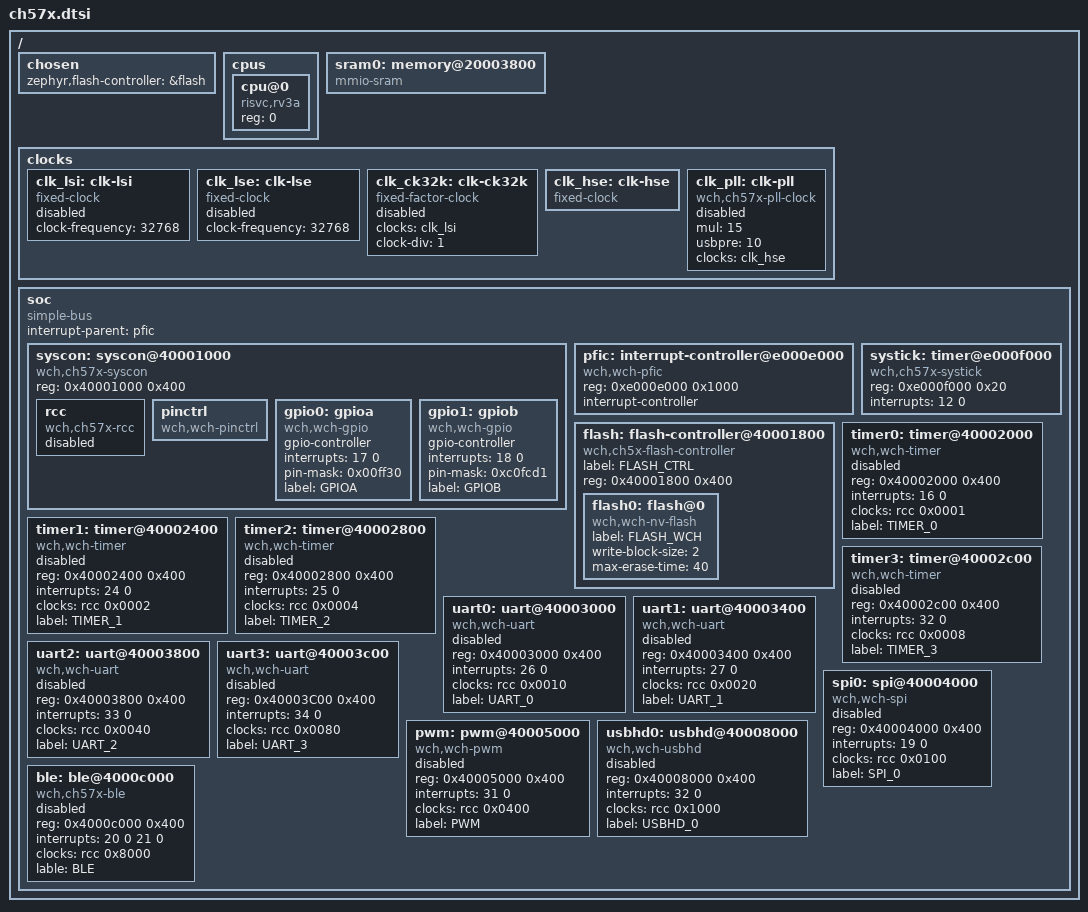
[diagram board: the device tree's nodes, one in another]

#include "skeleton.dtsi"
#include <freq.h>

/ {
	chosen {
		zephyr,flash-controller = &flash;
	};

	cpus {
		#address-cells = <1>;
		#size-cells = <0>;

		cpu@0 {
			device_type = "cpu";
			compatible = "risvc,rv3a";
			reg = <0>;
		};
	};

	sram0: memory@20003800 {
		compatible = "mmio-sram";
	};
	
	clocks {
		clk_lsi: clk-lsi {
			#clock-cells = <0>;
			compatible = "fixed-clock";
			clock-frequency = <32768>;
			status = "disabled";
		};

		clk_lse: clk-lse {
			#clock-cells = <0>;
			compatible = "fixed-clock";
			clock-frequency = <32768>;
			status = "disabled";
		};

		clk_ck32k: clk-ck32k {
			#clock-cells = <0>;
			compatible = "fixed-factor-clock";
			clocks = <&clk_lsi>;
			clock-div = <1>;
			status = "disabled";
		};

		clk_hse: clk-hse {
			#clock-cells = <0>;
			compatible = "fixed-clock";
		};

		clk_pll: clk-pll {
			#clock-cells = <0>;
			compatible = "wch,ch57x-pll-clock";
			mul = <15>;
			usbpre = <10>;
			clocks = <&clk_hse>;
			status = "disabled";
		};
	};

	soc {
		#address-cells = <1>;
		#size-cells = <1>;
		compatible = "simple-bus";
		interrupt-parent = <&pfic>;
		ranges;

		syscon: syscon@40001000 {
			compatible = "wch,ch57x-syscon";
			reg = <0x40001000 0x400>;

			rcc: rcc {
				#clock-cells = <1>;
				compatible = "wch,ch57x-rcc";
				status = "disabled";
			};

			pinctrl: pinctrl {
				compatible = "wch,wch-pinctrl";
			};

			gpio0: gpioa {
				compatible = "wch,wch-gpio";
				gpio-controller;
				#gpio-cells = <2>;
				interrupts = <17 0>;
				pin-mask = <0x00ff30>;
				label = "GPIOA";
			};

			gpio1: gpiob {
				compatible = "wch,wch-gpio";
				gpio-controller;
				#gpio-cells = <2>;
				interrupts = <18 0>;
				pin-mask = <0xc0fcd1>;
				label = "GPIOB";
			};
		};

		pfic: interrupt-controller@e000e000  {
			#address-cells = <1>;
			compatible = "wch,wch-pfic";
			reg = <0xe000e000 0x1000>;
			interrupt-controller;
			//num-irq-priority-bits = <8>;
			#interrupt-cells = <2>;
		};

		systick: timer@e000f000 {
			compatible = "wch,ch57x-systick";
			reg = <0xe000f000 0x20>;
			interrupts = <12 0>;
		};

		flash: flash-controller@40001800 {
			compatible = "wch,ch5x-flash-controller", "wch,ch57x-flash-controller";
			label = "FLASH_CTRL";
			reg = <0x40001800 0x400>;

			#address-cells = <1>;
			#size-cells = <1>;

			flash0: flash@0 {
				compatible = "wch,wch-nv-flash", "soc_nv_flash";
				label = "FLASH_WCH";

				write-block-size = <2>;
				/* maximum erase time for a 2K sector */
				max-erase-time = <40>;
			};
		};

		timer0: timer@40002000 {
			compatible = "wch,wch-timer";
			reg = <0x40002000 0x400>;
			interrupts = <16 0>;
			clocks = <&rcc 0x0001>;
			label = "TIMER_0";
			status = "disabled";
		};

		timer1: timer@40002400 {
			compatible = "wch,wch-timer";
			reg = <0x40002400 0x400>;
			interrupts = <24 0>;
			clocks = <&rcc 0x0002>;
			label = "TIMER_1";
			status = "disabled";
		};

		timer2: timer@40002800 {
			compatible = "wch,wch-timer";
			reg = <0x40002800 0x400>;
			interrupts = <25 0>;
			clocks = <&rcc 0x0004>;
			label = "TIMER_2";
			status = "disabled";
		};

		timer3: timer@40002c00 {
			compatible = "wch,wch-timer";
			reg = <0x40002c00 0x400>;
			interrupts = <32 0>;
			clocks = <&rcc 0x0008>;
			label = "TIMER_3";
			status = "disabled";
		};


		/* clk and pinctl */
		uart0: uart@40003000 {
			compatible = "wch,wch-uart";
			reg = <0x40003000 0x400>;
			interrupts = <26 0>;
			clocks = <&rcc 0x0010>;
			label = "UART_0";
			//support-half-duplex = <1>;
			status = "disabled";
		};

		uart1: uart@40003400 {
			compatible = "wch,wch-uart";
			reg = <0x40003400 0x400>;
			interrupts = <27 0>;
			clocks = <&rcc 0x0020>;
			label = "UART_1";
			status = "disabled";
		};

		uart2: uart@40003800 {
			compatible = "wch,wch-uart";
			reg = <0x40003800 0x400>;
			interrupts = <33 0>;
			clocks = <&rcc 0x0040>;
			label = "UART_2";
			status = "disabled";
		};

		uart3: uart@40003c00 {
			compatible = "wch,wch-uart";
			reg = <0x40003C00 0x400>;
			interrupts = <34 0>;
			clocks = <&rcc 0x0080>;
			label = "UART_3";
			status = "disabled";
		};

		spi0: spi@40004000 {
			compatible = "wch,wch-spi";
			reg = <0x40004000 0x400>;
			interrupts = <19 0>;
			clocks = <&rcc 0x0100>;
			label = "SPI_0";
			status = "disabled";
		};

		pwm: pwm@40005000 {
			compatible = "wch,wch-pwm";
			reg = <0x40005000 0x400>;
			interrupts = <31 0>;
			clocks = <&rcc 0x0400>;
			label = "PWM";
			status = "disabled";
		};

		usbhd0: usbhd@40008000 {
			compatible = "wch,wch-usbhd";
			reg = <0x40008000 0x400>;
			interrupts = <32 0>;
			clocks = <&rcc 0x1000>;
			label = "USBHD_0";
			status = "disabled";
		};

		ble: ble@4000c000 {
			compatible = "wch,ch57x-ble";
			reg = <0x4000c000 0x400>;
			interrupts = <20 0 21 0>;
			clocks = <&rcc 0x8000>;
			lable = "BLE";
			status = "disabled";
		};

	};
};
